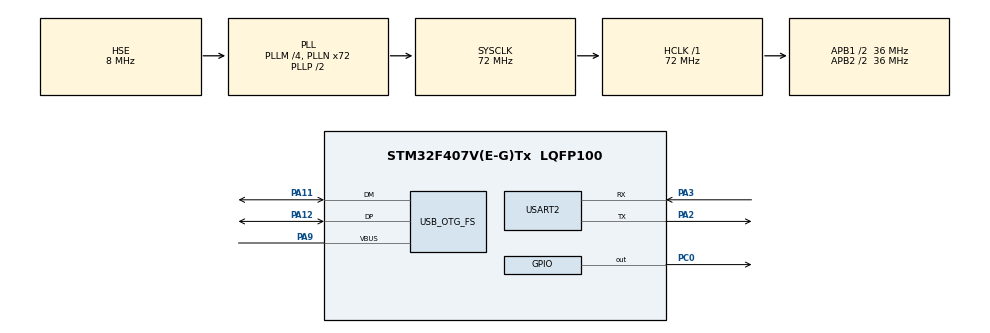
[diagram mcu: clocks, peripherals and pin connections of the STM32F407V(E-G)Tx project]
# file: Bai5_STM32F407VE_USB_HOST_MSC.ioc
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Mcu.Family=STM32F4
PH0-OSC_IN.Signal=RCC_OSC_IN
RCC.CortexFreq_Value=72000000
FATFS._USE_LFN=1
VP_USB_HOST_VS_USB_HOST_MSC_FS.Mode=MSC_FS
USB_HOST0.BSP.solution=PC0
USB_HOST.BSP.number=1
PA11.Mode=Host_Only
PC0.Signal=GPIO_Output
RCC.APB1CLKDivider=RCC_HCLK_DIV2
USB_HOST.USBH_HandleTypeDef-MSC_FS=hUsbHostFS
RCC.SYSCLKSource=RCC_SYSCLKSOURCE_PLLCLK
ProjectManager.StackSize=0x400
USB_HOST0.BSP.STBoard=false
PA13.Signal=SYS_JTMS-SWDIO
PA3.Mode=Asynchronous
PA9.Mode=Activate_VBUS
PA12.Signal=USB_OTG_FS_DP
ProjectManager.TargetToolchain=MDK-ARM V5
RCC.HCLKFreq_Value=72000000
RCC.APB2TimFreq_Value=72000000
PA9.Signal=USB_OTG_FS_VBUS
USB_HOST0.BSP.ip=GPIO
RCC.LSE_VALUE=32768
RCC.AHBFreq_Value=72000000
PH0-OSC_IN.Mode=HSE-External-Oscillator
RCC.HSE_VALUE=8000000
USB_OTG_FS.phy_itface=HCD_PHY_EMBEDDED
board=custom
RCC.VCOOutputFreq_Value=144000000
USB_HOST.VirtualModeFS=Msc
RCC.APB2Freq_Value=36000000
USB_HOST0.BSP.api=Unknown
FATFS._FS_EXFAT=1
PA14.Mode=Serial_Wire
PH1-OSC_OUT.Signal=RCC_OSC_OUT
PA13.Mode=Serial_Wire
Mcu.Name=STM32F407V(E-G)Tx
PA2.Signal=USART2_TX
FATFS._MAX_SS=4096
PH1-OSC_OUT.Mode=HSE-External-Oscillator
RCC.48MHZClocksFreq_Value=48000000
USB_HOST0.BSP.i2caddr=0
RCC.SYSCLKFreq_VALUE=72000000
Mcu.Package=LQFP100
PA12.Mode=Host_Only
USART2.VirtualMode=VM_ASYNC
NVIC.OTG_FS_IRQn=true\:0\:0\:false\:false\:true\:false\:true
PA11.Signal=USB_OTG_FS_DM
PA14.Signal=SYS_JTCK-SWCLK
USB_OTG_FS.VirtualMode=Host_Only
ProjectManager.HeapSize=0x200
VP_FATFS_VS_USB.Mode=USB
RCC.HSI_VALUE=16000000
RCC.PLLQ=3
NVIC.PriorityGroup=NVIC_PRIORITYGROUP_4
USB_HOST0.BSP.name=Drive_VBUS_FS
RCC.APB2CLKDivider=RCC_HCLK_DIV2
RCC.PLLM=4
RCC.PLLN=72
RCC.APB1TimFreq_Value=72000000
PA2.Mode=Asynchronous
RCC.APB1Freq_Value=36000000
USB_HOST0.BSP.mode=Output
PA3.Signal=USART2_RX
USB_HOST0.BSP.instance=PC0

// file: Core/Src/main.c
/* USER CODE BEGIN Header */
/**
  ******************************************************************************
  * @file           : main.c
  * @brief          : Main program body
  ******************************************************************************
  * @attention
  *
  * <h2><center>&copy; Copyright (c) 2022 STMicroelectronics.
  * All rights reserved.</center></h2>
  *
  * This software component is licensed by ST under Ultimate Liberty license
  * SLA0044, the "License"; You may not use this file except in compliance with
  * the License. You may obtain a copy of the License at:
  *                             www.st.com/SLA0044
  *
  ******************************************************************************
  */
/* USER CODE END Header */
#include "main.h"
#include "fatfs.h"
#include "usb_host.h"

/* USER CODE BEGIN Includes */
#include "USB_MSC_HOST_Handle.h"
/* USER CODE END Includes */

UART_HandleTypeDef huart2;

void SystemClock_Config(void);
static void MX_GPIO_Init(void);
static void MX_USART2_UART_Init(void);
void MX_USB_HOST_Process(void);

int main(void)
{

  /* MCU Configuration--------------------------------------------------------*/

  /* Reset of all peripherals, Initializes the Flash interface and the Systick. */
  HAL_Init();

  /* Configure the system clock */
  SystemClock_Config();

  /* Initialize all configured peripherals */
  MX_GPIO_Init();
  MX_USB_HOST_Init();
  MX_FATFS_Init();
  MX_USART2_UART_Init();

  /* Infinite loop */
  while (1)
  {
    MX_USB_HOST_Process();

  }
}

void SystemClock_Config(void)
{
  RCC_OscInitTypeDef RCC_OscInitStruct = {0};
  RCC_ClkInitTypeDef RCC_ClkInitStruct = {0};

  /** Configure the main internal regulator output voltage
  */
  __HAL_RCC_PWR_CLK_ENABLE();
  __HAL_PWR_VOLTAGESCALING_CONFIG(PWR_REGULATOR_VOLTAGE_SCALE1);
  /** Initializes the RCC Oscillators according to the specified parameters
  * in the RCC_OscInitTypeDef structure.
  */
  RCC_OscInitStruct.OscillatorType = RCC_OSCILLATORTYPE_HSE;
  RCC_OscInitStruct.HSEState = RCC_HSE_ON;
  RCC_OscInitStruct.PLL.PLLState = RCC_PLL_ON;
  RCC_OscInitStruct.PLL.PLLSource = RCC_PLLSOURCE_HSE;
  RCC_OscInitStruct.PLL.PLLM = 4;
  RCC_OscInitStruct.PLL.PLLN = 72;
  RCC_OscInitStruct.PLL.PLLP = RCC_PLLP_DIV2;
  RCC_OscInitStruct.PLL.PLLQ = 3;
  if (HAL_RCC_OscConfig(&RCC_OscInitStruct) != HAL_OK)
  {
    Error_Handler();
  }
  /** Initializes the CPU, AHB and APB buses clocks
  */
  RCC_ClkInitStruct.ClockType = RCC_CLOCKTYPE_HCLK|RCC_CLOCKTYPE_SYSCLK
                              |RCC_CLOCKTYPE_PCLK1|RCC_CLOCKTYPE_PCLK2;
  RCC_ClkInitStruct.SYSCLKSource = RCC_SYSCLKSOURCE_PLLCLK;
  RCC_ClkInitStruct.AHBCLKDivider = RCC_SYSCLK_DIV1;
  RCC_ClkInitStruct.APB1CLKDivider = RCC_HCLK_DIV2;
  RCC_ClkInitStruct.APB2CLKDivider = RCC_HCLK_DIV2;

  if (HAL_RCC_ClockConfig(&RCC_ClkInitStruct, FLASH_LATENCY_2) != HAL_OK)
  {
    Error_Handler();
  }
}

static void MX_USART2_UART_Init(void)
{

  huart2.Instance = USART2;
  huart2.Init.BaudRate = 115200;
  huart2.Init.WordLength = UART_WORDLENGTH_8B;
  huart2.Init.StopBits = UART_STOPBITS_1;
  huart2.Init.Parity = UART_PARITY_NONE;
  huart2.Init.Mode = UART_MODE_TX_RX;
  huart2.Init.HwFlowCtl = UART_HWCONTROL_NONE;
  huart2.Init.OverSampling = UART_OVERSAMPLING_16;
  if (HAL_UART_Init(&huart2) != HAL_OK)
  {
    Error_Handler();
  }

}

static void MX_GPIO_Init(void)
{
  GPIO_InitTypeDef GPIO_InitStruct = {0};

  /* GPIO Ports Clock Enable */
  __HAL_RCC_GPIOH_CLK_ENABLE();
  __HAL_RCC_GPIOC_CLK_ENABLE();
  __HAL_RCC_GPIOA_CLK_ENABLE();

  /*Configure GPIO pin Output Level */
  HAL_GPIO_WritePin(GPIOC, GPIO_PIN_0, GPIO_PIN_RESET);

  /*Configure GPIO pin : PC0 */
  GPIO_InitStruct.Pin = GPIO_PIN_0;
  GPIO_InitStruct.Mode = GPIO_MODE_OUTPUT_PP;
  GPIO_InitStruct.Pull = GPIO_NOPULL;
  GPIO_InitStruct.Speed = GPIO_SPEED_FREQ_LOW;
  HAL_GPIO_Init(GPIOC, &GPIO_InitStruct);

}

void Error_Handler(void)
{
  __disable_irq();
  while (1)
  {
  }
}

/************************ (C) COPYRIGHT STMicroelectronics *****END OF FILE****/
